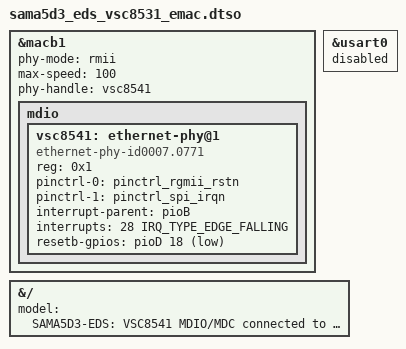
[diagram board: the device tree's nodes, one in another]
// SPDX-License-Identifier: (GPL-2.0+ OR MIT)
/*
 * sama5d3_eds_vsc8541 emac.dtso - Device Tree file for SAMA5D3 EDS board
 * overlay blob for the VSC8541/VSC8531 Evaluation Board.
 *
 * Copyright (C) 2023 Microchip Technology Inc. and its subsidiaries
 *
 * Author: Joemel John A Diente <JoemelJohn.Diente@microchip.com>
 *
 * Single-port 1000BASE-Tx Gigabit Ethernet PHY
 * https://www.microchip.com/en-us/product/VSC8541
 *
 */
/dts-v1/;
/plugin/;

#include "dt-bindings/gpio/gpio.h"
#include "dt-bindings/interrupt-controller/irq.h"
#include "dt-bindings/pinctrl/at91.h"

&macb1 {
	phy-mode = "rmii";
	max-speed = <100>;
	phy-handle = <&vsc8541>;
	status = "okay";

	mdio {
		#address-cells = <1>;
		#size-cells = <0>;

		vsc8541: ethernet-phy@1 { //PHY address VSC8541/VSC8531 Evaluation board is 0x1 and 0x00 respectively
			reg = <0x1>;
			compatible = "ethernet-phy-id0007.0771"; 
			pinctrl-0 = <&pinctrl_rgmii_rstn>;
			pinctrl-1 = <&pinctrl_spi_irqn>;
			interrupt-parent = <&pioB>;
			interrupts = <28 IRQ_TYPE_EDGE_FALLING>;
			resetb-gpios = <&pioD 18 GPIO_ACTIVE_LOW>;
			status = "okay";
		};
	};
};

// &macb1 {
// 	status = "disabled";
// };

&usart0 {
	status = "disabled";    /* Conflicts with using pioD 18 as GPIO */
};

&{/} {
	model = "SAMA5D3-EDS: VSC8541 MDIO/MDC connected to EMAC (RMII) For Testing Purposes Only";
};
